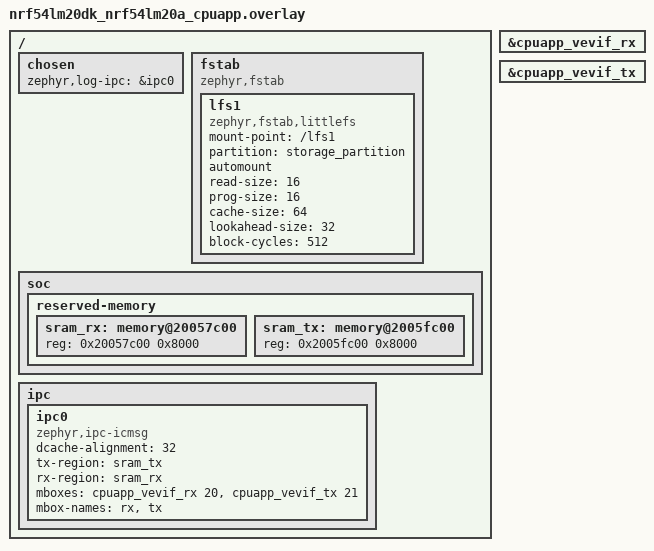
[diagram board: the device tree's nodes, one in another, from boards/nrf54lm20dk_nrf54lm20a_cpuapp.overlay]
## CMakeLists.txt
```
#
# Copyright (c) 2026 Nordic Semiconductor
#
# SPDX-License-Identifier: LicenseRef-Nordic-5-Clause
#

cmake_minimum_required(VERSION 3.20.0)

find_package(Zephyr REQUIRED HINTS $ENV{ZEPHYR_BASE})
project(multidomain_backends)

target_sources(app PRIVATE
  src/main.c
  src/cpuapp_verbose.c
  src/fs_dump_ble.c
)
```

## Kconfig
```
#
# Copyright (c) 2026 Nordic Semiconductor
#
# SPDX-License-Identifier: LicenseRef-Nordic-5-Clause
#

mainmenu "Multi-domain backends sample"

source "Kconfig.zephyr"

menu "Sample configuration"

config MULTIDOMAIN_BACKENDS_DICTIONARY_LOGGING
	bool "Enable dictionary output on all enabled log backends"
	default n
	select LOG_DICTIONARY_SUPPORT
	imply LOG_FMT_SECTION
	imply LOG_FMT_SECTION_STRIP if !LOG_ALWAYS_RUNTIME
	help
	  Enables dictionary mode output for UART, BLE, and filesystem backends.
	  This is useful when collecting compact log streams for host-side decoding.

endmenu
```

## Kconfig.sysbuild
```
#
# Copyright (c) 2026 Nordic Semiconductor
#
# SPDX-License-Identifier: LicenseRef-Nordic-5-Clause
#

config PARTITION_MANAGER
	default n

config REMOTE_BOARD
	string
	default "nrf54lm20dk/nrf54lm20a/cpuflpr" if BOARD_NRF54LM20DK_NRF54LM20A_CPUAPP

source "share/sysbuild/Kconfig"
```

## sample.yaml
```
sample:
  description: Multi-domain logging sample with UART, BLE, and filesystem backends plus runtime filtering.
  name: Multi-domain logging backends (nRF54LM20)

common:
  sysbuild: true
  tags:
    - logging
    - bluetooth
    - filesystem
    - ipc

tests:
  sample.logging.multidomain_backends.nrf54lm20:
    extra_args:
      - multidomain_backends_SNIPPET=nordic-flpr
    platform_allow:
      - nrf54lm20dk/nrf54lm20a/cpuapp
    integration_platforms:
      - nrf54lm20dk/nrf54lm20a/cpuapp
```

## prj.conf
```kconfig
CONFIG_ASSERT=y
CONFIG_PRINTK=y
CONFIG_HEAP_MEM_POOL_SIZE=8192
CONFIG_WARN_EXPERIMENTAL=n

CONFIG_IPC_SERVICE=y
CONFIG_IPC_SERVICE_BACKEND_ICMSG=y
CONFIG_MBOX=y
CONFIG_PBUF_RX_READ_BUF_SIZE=256
CONFIG_IPC_SERVICE_BACKEND_ICMSG_WQ_STACK_SIZE=2048

CONFIG_LOG=y
CONFIG_LOG_MODE_DEFERRED=y
CONFIG_LOG_RUNTIME_FILTERING=y
CONFIG_LOG_MULTIDOMAIN=y
CONFIG_LOG_LINK_IPC_SERVICE=y
CONFIG_LOG_BUFFER_SIZE=16384
CONFIG_LOG_PROCESS_THREAD_STACK_SIZE=4096
CONFIG_LOG_PROCESSING_LATENCY_US=300000
CONFIG_LOG_MAX_LEVEL=3
CONFIG_LOG_DEFAULT_LEVEL=3
CONFIG_LOG_OVERRIDE_LEVEL=3
CONFIG_LOG_DOMAIN_NAME="cpuapp"

CONFIG_LOG_BACKEND_UART=y
CONFIG_LOG_BACKEND_UART_AUTOSTART=n
CONFIG_LOG_BACKEND_BLE=y
CONFIG_LOG_BACKEND_FS=y
CONFIG_LOG_BACKEND_RTT=n

CONFIG_LOG_BACKEND_FS_DIR="/lfs1"
CONFIG_LOG_BACKEND_FS_FILE_PREFIX="err."
CONFIG_LOG_BACKEND_FS_FILE_SIZE=2048
CONFIG_LOG_BACKEND_FS_FILES_LIMIT=4
CONFIG_LOG_BACKEND_FS_OVERWRITE=y
CONFIG_LOG_BACKEND_FS_AUTOSTART=n

CONFIG_FLASH=y
CONFIG_FLASH_MAP=y
CONFIG_FILE_SYSTEM=y
CONFIG_FILE_SYSTEM_LITTLEFS=y

CONFIG_BT=y
CONFIG_BT_SMP=y
CONFIG_BT_PERIPHERAL=y
CONFIG_BT_DEVICE_NAME="nRF54LM20 Multi-domain Logger"
CONFIG_BT_MAX_CONN=1
CONFIG_BT_MAX_PAIRED=1

CONFIG_TEST_RANDOM_GENERATOR=y
```

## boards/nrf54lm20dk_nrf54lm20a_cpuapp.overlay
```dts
/*
 * Copyright (c) 2026 Nordic Semiconductor
 *
 * SPDX-License-Identifier: LicenseRef-Nordic-5-Clause
 */

/ {
	chosen {
		zephyr,log-ipc = &ipc0;
	};

	fstab {
		compatible = "zephyr,fstab";

		lfs1: lfs1 {
			compatible = "zephyr,fstab,littlefs";
			mount-point = "/lfs1";
			partition = <&storage_partition>;
			automount;
			read-size = <16>;
			prog-size = <16>;
			cache-size = <64>;
			lookahead-size = <32>;
			block-cycles = <512>;
		};
	};

	soc {
		reserved-memory {
			#address-cells = <1>;
			#size-cells = <1>;

			sram_rx: memory@20057c00 {
				reg = <0x20057c00 0x8000>;
			};

			sram_tx: memory@2005fc00 {
				reg = <0x2005fc00 0x8000>;
			};
		};
	};

	ipc {
		ipc0: ipc0 {
			compatible = "zephyr,ipc-icmsg";
			dcache-alignment = <32>;
			tx-region = <&sram_tx>;
			rx-region = <&sram_rx>;
			mboxes = <&cpuapp_vevif_rx 20>, <&cpuapp_vevif_tx 21>;
			mbox-names = "rx", "tx";
			status = "okay";
		};
	};
};

&cpuapp_vevif_rx {
	status = "okay";
};

&cpuapp_vevif_tx {
	status = "okay";
};
```

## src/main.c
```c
/*
 * Copyright (c) 2026 Nordic Semiconductor
 *
 * SPDX-License-Identifier: LicenseRef-Nordic-5-Clause
 */

#include <stdbool.h>
#include <stdint.h>
#include <string.h>

#include <zephyr/kernel.h>
#include <zephyr/fs/fs.h>
#include <zephyr/sys/printk.h>
#include <zephyr/sys/iterable_sections.h>

#include <zephyr/bluetooth/bluetooth.h>
#include <zephyr/bluetooth/conn.h>
#include <zephyr/bluetooth/hci.h>
#include <zephyr/bluetooth/gatt.h>

#include <zephyr/logging/log.h>
#include <zephyr/logging/log_backend.h>
#include <zephyr/logging/log_backend_ble.h>
#include <zephyr/logging/log_ctrl.h>
#include <zephyr/logging/log_link.h>
#include <zephyr/logging/log_output.h>

#include "cpuapp_verbose.h"
#include "fs_dump_ble.h"

LOG_MODULE_REGISTER(cpuapp_main, LOG_LEVEL_INF);

static const struct bt_data ad[] = {
	BT_DATA_BYTES(BT_DATA_FLAGS, (BT_LE_AD_GENERAL | BT_LE_AD_NO_BREDR)),
	BT_DATA_BYTES(BT_DATA_UUID128_ALL, LOGGER_BACKEND_BLE_ADV_UUID_DATA),
};

static const struct bt_data sd[] = {
	BT_DATA(BT_DATA_NAME_COMPLETE, CONFIG_BT_DEVICE_NAME,
		sizeof(CONFIG_BT_DEVICE_NAME) - 1),
};

static const char * const app_prefixes[] = {
	"cpuapp_main",
	"cpuflpr_main",
};

static const char * const verbose_prefixes[] = {
	"cpuapp_verbose",
	"cpuflpr_verbose",
};

static const struct log_backend *uart_backend;
static const struct log_backend *ble_backend;
static const struct log_backend *fs_backend;

static bool ble_verbose_enabled;
static uint8_t routed_domains;
static void start_adv(void);
static void adv_restart_handler(struct k_work *work);
K_WORK_DELAYABLE_DEFINE(adv_restart_work, adv_restart_handler);

static uint8_t active_domain_count(void)
{
	uint8_t cnt = 1U;

#if defined(CONFIG_LOG_MULTIDOMAIN)
	STRUCT_SECTION_FOREACH(log_link, link) {
		if (log_link_is_active(link) == 0) {
			cnt += log_link_domains_count(link);
		}
	}
#endif

	return cnt;
}

static bool name_has_prefix(const char *name, const char *prefix)
{
	return name && prefix && (strncmp(name, prefix, strlen(prefix)) == 0);
}

static bool source_matches(const char *name, const char * const prefixes[], size_t prefix_cnt)
{
	for (size_t i = 0; i < prefix_cnt; i++) {
		if (name_has_prefix(name, prefixes[i])) {
			return true;
		}
	}

	return false;
}

static const struct log_backend *backend_find(const char *prefix)
{
	size_t len = strlen(prefix);

	STRUCT_SECTION_FOREACH(log_backend, backend) {
		if (strncmp(prefix, backend->name, len) == 0) {
			return backend;
		}
	}

	return NULL;
}

static void set_all_sources_level(const struct log_backend *backend, uint32_t level)
{
	uint8_t domains = active_domain_count();

	for (uint8_t d = 0; d < domains; d++) {
		uint16_t src_cnt = log_src_cnt_get(d);

		for (uint16_t s = 0; s < src_cnt; s++) {
			(void)log_filter_set(backend, d, s, level);
		}
	}
}

static void set_matching_sources_level(const struct log_backend *backend,
				       const char * const prefixes[],
				       size_t prefix_cnt,
				       uint32_t level)
{
	uint8_t domains = active_domain_count();

	for (uint8_t d = 0; d < domains; d++) {
		uint16_t src_cnt = log_src_cnt_get(d);

		for (uint16_t s = 0; s < src_cnt; s++) {
			const char *name = log_source_name_get(d, s);

			if (source_matches(name, prefixes, prefix_cnt)) {
				(void)log_filter_set(backend, d, s, level);
			}
		}
	}
}

static void apply_base_routing_filters(void)
{
	if (uart_backend) {
		set_all_sources_level(uart_backend, LOG_LEVEL_ERR);
		set_matching_sources_level(uart_backend, app_prefixes,
					   ARRAY_SIZE(app_prefixes), LOG_LEVEL_INF);
	}

	if (fs_backend) {
		set_all_sources_level(fs_backend, LOG_LEVEL_NONE);
		set_matching_sources_level(fs_backend, app_prefixes,
					   ARRAY_SIZE(app_prefixes), LOG_LEVEL_ERR);
	}

	if (ble_backend) {
		set_all_sources_level(ble_backend, LOG_LEVEL_NONE);
		set_matching_sources_level(ble_backend, app_prefixes,
					   ARRAY_SIZE(app_prefixes), LOG_LEVEL_INF);
		if (ble_verbose_enabled) {
			set_matching_sources_level(ble_backend, verbose_prefixes,
						   ARRAY_SIZE(verbose_prefixes), LOG_LEVEL_INF);
		}
	}

	routed_domains = active_domain_count();
}

static void refresh_filters_if_domains_changed(void)
{
	uint8_t active_domains = active_domain_count();

	if (active_domains == routed_domains) {
		return;
	}

	apply_base_routing_filters();
	LOG_INF("Re-applied routing filters for %u active domain(s)", active_domains);
}

#if defined(CONFIG_MULTIDOMAIN_BACKENDS_DICTIONARY_LOGGING)
static void configure_dictionary_mode(void)
{
	int err;

	if (uart_backend) {
		err = log_backend_format_set(uart_backend, LOG_OUTPUT_DICT);
		LOG_INF("UART dictionary mode set: %d", err);
	}

	if (ble_backend) {
		err = log_backend_format_set(ble_backend, LOG_OUTPUT_DICT);
		LOG_INF("BLE dictionary mode set: %d", err);
	}

	if (fs_backend) {
		err = log_backend_format_set(fs_backend, LOG_OUTPUT_DICT);
		LOG_INF("FS dictionary mode set: %d", err);
	}
}
#else
static inline void configure_dictionary_mode(void)
{
}
#endif

static void wait_for_remote_domain(void)
{
	uint32_t waited_ms = 0U;
	const uint8_t expected_domains = 2U;

	while ((active_domain_count() < expected_domains) && (waited_ms < 5000U)) {
		k_sleep(K_MSEC(100));
		waited_ms += 100U;
	}

	if (active_domain_count() >= expected_domains) {
		LOG_INF("Domain count at filter setup: active=%u expected=%u",
			active_domain_count(), expected_domains);
	} else {
		LOG_WRN("Remote domain not active yet (active=%u expected=%u)",
			active_domain_count(), expected_domains);
	}
}

static void start_uart_backend(void)
{
	if (!uart_backend) {
		return;
	}

	if (!uart_backend->cb->initialized) {
		log_backend_init(uart_backend);
	}

	if (!log_backend_is_active(uart_backend)) {
		log_backend_enable(uart_backend, uart_backend->cb->ctx, LOG_LEVEL_NONE);
	}
}

static void purge_fs_log_files(void)
{
	struct fs_dir_t dir;
	struct fs_dirent ent;
	int err;
	char path[96];

	fs_dir_t_init(&dir);
	err = fs_opendir(&dir, CONFIG_LOG_BACKEND_FS_DIR);
	if (err != 0) {
		LOG_WRN("FS cleanup skipped (opendir err %d)", err);
		return;
	}

	while (true) {
		err = fs_readdir(&dir, &ent);
		if ((err != 0) || (ent.name[0] == '\0')) {
			break;
		}

		if (ent.type != FS_DIR_ENTRY_FILE) {
			continue;
		}

		int len = snprintk(path, sizeof(path), "%s/%s",
				  CONFIG_LOG_BACKEND_FS_DIR, ent.name);
		if ((len > 0) && (len < (int)sizeof(path))) {
			(void)fs_unlink(path);
		}
	}

	(void)fs_closedir(&dir);
}

static void start_fs_backend(void)
{
	if (!fs_backend) {
		return;
	}

	purge_fs_log_files();
	if (!fs_backend->cb->initialized) {
		log_backend_init(fs_backend);
	}
	if (!log_backend_is_active(fs_backend)) {
		log_backend_enable(fs_backend, fs_backend->cb->ctx, LOG_LEVEL_NONE);
	}
	LOG_INF("FS backend enabled");
}

static void enable_ble_verbose_modules(void)
{
	if (!ble_backend || ble_verbose_enabled) {
		return;
	}

	ble_verbose_enabled = true;
	set_matching_sources_level(ble_backend, verbose_prefixes,
				   ARRAY_SIZE(verbose_prefixes), LOG_LEVEL_INF);
	LOG_INF("BLE runtime filtering: enabled INF for verbose modules");
}

static void ble_notify_hook(bool status, void *ctx)
{
	ARG_UNUSED(ctx);
	LOG_INF("BLE backend notifications %s", status ? "enabled" : "disabled");
}

static void connected(struct bt_conn *conn, uint8_t err)
{
	ARG_UNUSED(conn);

	if (err) {
		LOG_WRN("BLE connect failed (%u)", err);
		return;
	}

	LOG_INF("BLE connected");
}

static void disconnected(struct bt_conn *conn, uint8_t reason)
{
	ARG_UNUSED(conn);

	LOG_INF("BLE disconnected (reason 0x%02x), scheduling advertising restart", reason);
	(void)k_work_reschedule(&adv_restart_work, K_MSEC(100));
}

BT_CONN_CB_DEFINE(multidomain_backends_conn_cb) = {
	.connected = connected,
	.disconnected = disconnected,
};

static void start_adv(void)
{
	int err = bt_le_adv_start(BT_LE_ADV_CONN_FAST_1,
				  ad, ARRAY_SIZE(ad), sd, ARRAY_SIZE(sd));

	if (err == -EALREADY) {
		LOG_INF("BLE advertising already active");
		return;
	}

	if ((err == -ENOMEM) || (err == -EAGAIN) || (err == -EBUSY)) {
		LOG_WRN("BLE advertising start busy (%d), retrying", err);
		(void)k_work_reschedule(&adv_restart_work, K_MSEC(200));
		return;
	}

	if (err) {
		LOG_ERR("BLE advertising start failed (%d)", err);
		return;
	}

	LOG_INF("BLE advertising started");
}

static void adv_restart_handler(struct k_work *work)
{
	ARG_UNUSED(work);
	start_adv();
}

static int setup_ble(void)
{
	int err;

	logger_backend_ble_set_hook(ble_notify_hook, NULL);

	err = bt_enable(NULL);
	if (err) {
		LOG_ERR("Bluetooth init failed (%d)", err);
		return err;
	}

	start_adv();

	return 0;
}

static void report_fs_status(void)
{
	struct fs_dirent ent;
	int err = fs_stat(CONFIG_LOG_BACKEND_FS_DIR, &ent);

	if ((err == 0) && (ent.type == FS_DIR_ENTRY_DIR)) {
		LOG_INF("Filesystem ready at %s", CONFIG_LOG_BACKEND_FS_DIR);
	} else {
		LOG_WRN("Filesystem not ready at %s (err %d)",
			CONFIG_LOG_BACKEND_FS_DIR, err);
	}
}

int main(void)
{
	uint32_t seq = 0U;

	uart_backend = backend_find("log_backend_uart");
	ble_backend = backend_find("log_backend_ble");
	fs_backend = backend_find("log_backend_fs");

	LOG_INF("multi-domain backend sample start (%s)", CONFIG_BOARD);
	LOG_INF("backend presence: uart=%d ble=%d fs=%d",
		uart_backend != NULL, ble_backend != NULL, fs_backend != NULL);
	LOG_INF("Demo cadence: app logs every 10 seconds");

	configure_dictionary_mode();
	fs_dump_ble_init();

	(void)setup_ble();
	report_fs_status();
	wait_for_remote_domain();
	start_uart_backend();
	start_fs_backend();
	apply_base_routing_filters();
	LOG_INF("Routing: UART(ERR all + app INF/WRN), BLE(app INF+), FS(app ERR)");
	LOG_ERR("demo startup marker: this error is intentionally stored in FS");

	while (1) {
		refresh_filters_if_domains_changed();

		if (seq == 20U) {
			enable_ble_verbose_modules();
		}

		LOG_INF("cpuapp info heartbeat seq=%u (10s cadence)", seq);
		if ((seq % 3U) == 0U) {
			LOG_WRN("cpuapp warning checkpoint seq=%u", seq);
		}
		if ((seq % 6U) == 0U) {
			LOG_ERR("cpuapp error checkpoint seq=%u", seq);
		}

		cpuapp_verbose_log(seq);

		seq++;
		k_sleep(K_SECONDS(10));
	}

	return 0;
}
```

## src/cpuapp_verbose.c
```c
/*
 * Copyright (c) 2026 Nordic Semiconductor
 *
 * SPDX-License-Identifier: LicenseRef-Nordic-5-Clause
 */

#include <zephyr/logging/log.h>
#include "cpuapp_verbose.h"

LOG_MODULE_REGISTER(cpuapp_verbose, LOG_LEVEL_INF);

void cpuapp_verbose_log(uint32_t seq)
{
	if ((seq % 4U) == 0U) {
		LOG_INF("cpuapp verbose info seq=%u", seq);
	}
}
```

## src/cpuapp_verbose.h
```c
/*
 * Copyright (c) 2026 Nordic Semiconductor
 *
 * SPDX-License-Identifier: LicenseRef-Nordic-5-Clause
 */

#ifndef CPUAPP_VERBOSE_H_
#define CPUAPP_VERBOSE_H_

#include <stdint.h>

void cpuapp_verbose_log(uint32_t seq);

#endif /* CPUAPP_VERBOSE_H_ */
```

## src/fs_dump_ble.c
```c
/*
 * Copyright (c) 2026 Nordic Semiconductor
 *
 * SPDX-License-Identifier: LicenseRef-Nordic-5-Clause
 */

#include <errno.h>
#include <stdbool.h>
#include <stddef.h>
#include <stdint.h>
#include <string.h>

#include <zephyr/bluetooth/bluetooth.h>
#include <zephyr/bluetooth/conn.h>
#include <zephyr/bluetooth/gatt.h>
#include <zephyr/fs/fs.h>
#include <zephyr/kernel.h>
#include <zephyr/sys/printk.h>

#include "fs_dump_ble.h"

#include <zephyr/logging/log.h>
LOG_MODULE_REGISTER(fs_dump_ble, LOG_LEVEL_INF);

#define FS_DUMP_CMD_MAX_LEN 64
#define FS_DUMP_PATH_MAX_LEN 96
#define FS_DUMP_READ_CHUNK 8

#define BT_UUID_FS_DUMP_SERVICE_VAL \
	BT_UUID_128_ENCODE(0x3a0b25f0, 0x8d4b, 0x4cde, 0x9f80, 0x7d3cf6f8a100)
#define BT_UUID_FS_DUMP_CMD_VAL \
	BT_UUID_128_ENCODE(0x3a0b25f1, 0x8d4b, 0x4cde, 0x9f80, 0x7d3cf6f8a100)
#define BT_UUID_FS_DUMP_DATA_VAL \
	BT_UUID_128_ENCODE(0x3a0b25f2, 0x8d4b, 0x4cde, 0x9f80, 0x7d3cf6f8a100)

static struct bt_uuid_128 fs_dump_service_uuid = BT_UUID_INIT_128(
	BT_UUID_FS_DUMP_SERVICE_VAL);
static struct bt_uuid_128 fs_dump_cmd_uuid = BT_UUID_INIT_128(
	BT_UUID_FS_DUMP_CMD_VAL);
static struct bt_uuid_128 fs_dump_data_uuid = BT_UUID_INIT_128(
	BT_UUID_FS_DUMP_DATA_VAL);

#define BT_UUID_FS_DUMP_SERVICE (&fs_dump_service_uuid.uuid)
#define BT_UUID_FS_DUMP_CMD (&fs_dump_cmd_uuid.uuid)
#define BT_UUID_FS_DUMP_DATA (&fs_dump_data_uuid.uuid)

static K_MUTEX_DEFINE(fs_dump_lock);
static struct bt_conn *fs_dump_conn;
static bool fs_dump_notify_enabled;
static char fs_dump_cmd_buf[FS_DUMP_CMD_MAX_LEN + 1];

static void fs_dump_work_handler(struct k_work *work);
static K_WORK_DEFINE(fs_dump_work, fs_dump_work_handler);

static const struct bt_gatt_attr *fs_dump_data_attr_get(void);

static size_t notify_payload_max(struct bt_conn *conn)
{
	uint16_t mtu = bt_gatt_get_mtu(conn);

	if (mtu <= 3U) {
		return 20U;
	}

	return mtu - 3U;
}

static int notify_raw(struct bt_conn *conn, const uint8_t *data, size_t len)
{
	return bt_gatt_notify(conn, fs_dump_data_attr_get(), data, len);
}

static int notify_text(struct bt_conn *conn, const char *text)
{
	size_t len = strlen(text);
	size_t pos = 0U;
	size_t chunk_max = notify_payload_max(conn);

	while (pos < len) {
		size_t chunk = MIN(chunk_max, len - pos);
		int err;
		int retries = 0;

		do {
			err = notify_raw(conn, (const uint8_t *)&text[pos], chunk);
			if ((err == -ENOMEM) || (err == -EAGAIN)) {
				k_sleep(K_MSEC(10));
				retries++;
			}
		} while (((err == -ENOMEM) || (err == -EAGAIN)) && (retries < 50));

		if (err) {
			return err;
		}

		pos += chunk;
		k_sleep(K_MSEC(2));
	}

	return 0;
}

static void notify_error_line(struct bt_conn *conn, const char *msg, int err)
{
	char line[64];

	snprintk(line, sizeof(line), "ERR %s (%d)\n", msg, err);
	(void)notify_text(conn, line);
}

static void ccc_cfg_changed(const struct bt_gatt_attr *attr, uint16_t value)
{
	ARG_UNUSED(attr);

	k_mutex_lock(&fs_dump_lock, K_FOREVER);
	fs_dump_notify_enabled = (value == BT_GATT_CCC_NOTIFY);
	k_mutex_unlock(&fs_dump_lock);

	LOG_INF("FS dump notifications %s", fs_dump_notify_enabled ? "enabled" : "disabled");
}

static ssize_t cmd_write(struct bt_conn *conn, const struct bt_gatt_attr *attr,
			 const void *buf, uint16_t len, uint16_t offset, uint8_t flags)
{
	uint16_t copy_len;

	ARG_UNUSED(attr);
	ARG_UNUSED(flags);

	if (conn == NULL) {
		return BT_GATT_ERR(BT_ATT_ERR_UNLIKELY);
	}

	if (offset != 0U) {
		return BT_GATT_ERR(BT_ATT_ERR_INVALID_OFFSET);
	}

	copy_len = MIN(len, (uint16_t)FS_DUMP_CMD_MAX_LEN);

	k_mutex_lock(&fs_dump_lock, K_FOREVER);

	memcpy(fs_dump_cmd_buf, buf, copy_len);
	fs_dump_cmd_buf[copy_len] = '\0';

	if (fs_dump_conn != NULL) {
		bt_conn_unref(fs_dump_conn);
	}
	fs_dump_conn = bt_conn_ref(conn);

	k_mutex_unlock(&fs_dump_lock);

	(void)k_work_submit(&fs_dump_work);

	return len;
}

BT_GATT_SERVICE_DEFINE(fs_dump_svc,
	BT_GATT_PRIMARY_SERVICE(BT_UUID_FS_DUMP_SERVICE),
	BT_GATT_CHARACTERISTIC(BT_UUID_FS_DUMP_CMD,
			       BT_GATT_CHRC_WRITE | BT_GATT_CHRC_WRITE_WITHOUT_RESP,
			       BT_GATT_PERM_WRITE, NULL, cmd_write, NULL),
	BT_GATT_CHARACTERISTIC(BT_UUID_FS_DUMP_DATA, BT_GATT_CHRC_NOTIFY,
			       BT_GATT_PERM_NONE, NULL, NULL, NULL),
	BT_GATT_CCC(ccc_cfg_changed, BT_GATT_PERM_READ | BT_GATT_PERM_WRITE),
);

static const struct bt_gatt_attr *fs_dump_data_attr_get(void)
{
	return &fs_dump_svc.attrs[4];
}

static const char *skip_spaces(const char *s)
{
	while ((*s == ' ') || (*s == '\t')) {
		s++;
	}

	return s;
}

static void trim_trailing(char *s)
{
	size_t len = strlen(s);

	while (len > 0U) {
		char c = s[len - 1U];

		if ((c != '\r') && (c != '\n') && (c != ' ') && (c != '\t')) {
			break;
		}

		s[len - 1U] = '\0';
		len--;
	}
}

static bool invalid_filename(const char *name)
{
	if ((name == NULL) || (name[0] == '\0')) {
		return true;
	}

	if ((strstr(name, "..") != NULL) || (strchr(name, '/') != NULL)) {
		return true;
	}

	return false;
}

static void handle_list(struct bt_conn *conn)
{
	int misses = 0;

	(void)notify_text(conn, "OK LIST BEGIN\n");

	for (int file_idx = 0; file_idx <= 9999; file_idx++) {
		struct fs_dirent ent;
		char file_name[20];
		char path[FS_DUMP_PATH_MAX_LEN];
		char line[64];
		int err;
		int path_len;

		snprintk(file_name, sizeof(file_name), "%s%04d",
			 CONFIG_LOG_BACKEND_FS_FILE_PREFIX, file_idx);
		path_len = snprintk(path, sizeof(path), "%s/%s",
				    CONFIG_LOG_BACKEND_FS_DIR, file_name);
		if ((path_len <= 0) || (path_len >= (int)sizeof(path))) {
			break;
		}

		err = fs_stat(path, &ent);
		if (err == 0) {
			misses = 0;
			snprintk(line, sizeof(line), "FILE %s\n", file_name);
			(void)notify_text(conn, line);
			continue;
		}

		misses++;

		/* Stop quickly after consecutive misses to keep LIST response short. */
		if (misses >= 8) {
			break;
		}
	}

	(void)notify_text(conn, "OK LIST END\n");
}

static void handle_dump(struct bt_conn *conn, const char *name)
{
	struct fs_file_t file;
	uint8_t read_buf[FS_DUMP_READ_CHUNK];
	char path[FS_DUMP_PATH_MAX_LEN];
	char chunk_line[2 + (FS_DUMP_READ_CHUNK * 2) + 2];
	char control_line[64];
	int path_len;
	int rd;

	if (invalid_filename(name)) {
		notify_error_line(conn, "DUMP invalid filename", -EINVAL);
		return;
	}

	path_len = snprintk(path, sizeof(path), "%s/%s", CONFIG_LOG_BACKEND_FS_DIR, name);
	if ((path_len <= 0) || (path_len >= (int)sizeof(path))) {
		notify_error_line(conn, "DUMP filename too long", -ENAMETOOLONG);
		return;
	}

	fs_file_t_init(&file);

	rd = fs_open(&file, path, FS_O_READ);
	if (rd != 0) {
		notify_error_line(conn, "DUMP open failed", rd);
		return;
	}

	snprintk(control_line, sizeof(control_line), "OK DUMP BEGIN %s\n", name);
	(void)notify_text(conn, control_line);

	while (true) {
		rd = fs_read(&file, read_buf, sizeof(read_buf));
		if (rd < 0) {
			notify_error_line(conn, "DUMP read failed", rd);
			break;
		}

		if (rd == 0) {
			break;
		}

		chunk_line[0] = 'D';
		chunk_line[1] = ' ';

		for (int i = 0; i < rd; i++) {
			snprintk(&chunk_line[2 + (i * 2)], 3, "%02x", read_buf[i]);
		}

		chunk_line[2 + (rd * 2)] = '\n';
		chunk_line[2 + (rd * 2) + 1] = '\0';
		(void)notify_text(conn, chunk_line);
	}

	(void)fs_close(&file);

	snprintk(control_line, sizeof(control_line), "OK DUMP END %s\n", name);
	(void)notify_text(conn, control_line);
}

static void fs_dump_work_handler(struct k_work *work)
{
	struct bt_conn *conn = NULL;
	char cmd[FS_DUMP_CMD_MAX_LEN + 1];
	const char *p;

	ARG_UNUSED(work);

	k_mutex_lock(&fs_dump_lock, K_FOREVER);

	if ((fs_dump_conn != NULL) && fs_dump_notify_enabled) {
		conn = bt_conn_ref(fs_dump_conn);
	}

	memcpy(cmd, fs_dump_cmd_buf, sizeof(cmd));

	k_mutex_unlock(&fs_dump_lock);

	if (conn == NULL) {
		return;
	}

	trim_trailing(cmd);
	p = skip_spaces(cmd);

	if (strcmp(p, "LIST") == 0) {
		handle_list(conn);
	} else if (strncmp(p, "DUMP", 4) == 0) {
		p = skip_spaces(p + 4);
		handle_dump(conn, p);
	} else {
		notify_error_line(conn, "Unknown command", -EINVAL);
	}

	bt_conn_unref(conn);
}

void fs_dump_ble_init(void)
{
	LOG_INF("BLE FS dump service ready (commands: LIST, DUMP <file>)");
}
```

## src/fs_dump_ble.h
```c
/*
 * Copyright (c) 2026 Nordic Semiconductor
 *
 * SPDX-License-Identifier: LicenseRef-Nordic-5-Clause
 */

#ifndef MULTIDOMAIN_BACKENDS_FS_DUMP_BLE_H_
#define MULTIDOMAIN_BACKENDS_FS_DUMP_BLE_H_

void fs_dump_ble_init(void);

#endif /* MULTIDOMAIN_BACKENDS_FS_DUMP_BLE_H_ */
```
